# M4K2A register map
File version: 0.1
Registers are 32-bit, read-write, reset 0x0 unless marked. A register's access mark holds for its fields unless they carry their own. Offsets are from the block's base; [hi:lo] are bit positions; {n}, {i} and the like mark numbered series.

## PC — Port C
Base 0x400C0200
0x00 DATA — PC Data Register
  [0] PC0
0x04 CR — PC Control Register
  [0] PC0C
0x08 FR1 — PC Function Register 1
  [0] PC0F1
0x0C FR2 — PC Function Register 2
  [0] PC0F2
0x14 FR4 — PC Function Register 4
  [0] PC0F4
0x18 FR5 — PC Function Register 5
  [0] PC0F5
0x28 OD — PC Open Drain Control Register
  [0] PC0OD
0x2C PUP — PC Pull-up Control Register
  [0] PC0PUP
0x30 PDN — PC Pull-Down Control Register
  [0] PC0PDN
0x38 IE — PC Input Enable Control Register
  [0] PC0IE

## PD — Port D
Base 0x400C0300
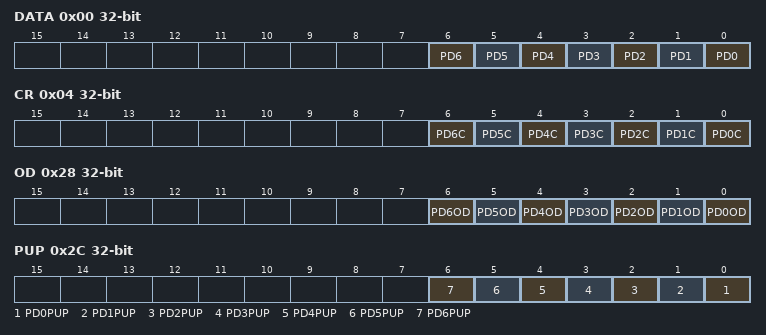
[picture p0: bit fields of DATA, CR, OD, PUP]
0x00 DATA — PD Data Register
  [n] PD{n} (n=0..6)
0x04 CR — PD Control Register
  [n] PD{n}C (n=0..6)
0x18 FR5 — PD Function Register 5
  [6] PD6F5
0x28 OD — PD Open Drain Control Register
  [n] PD{n}OD (n=0..6)
0x2C PUP — PD Pull-up Control Register
  [n] PD{n}PUP (n=0..6)
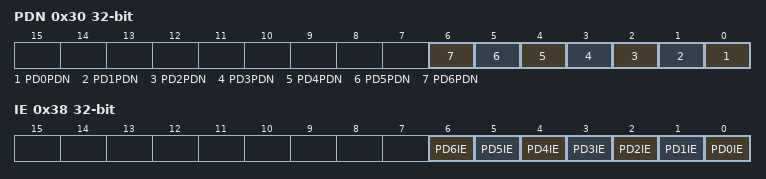
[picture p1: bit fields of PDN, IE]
0x30 PDN — PD Pull-Down Control Register
  [n] PD{n}PDN (n=0..6)
0x38 IE — PD Input Enable Control Register
  [n] PD{n}IE (n=0..6)

## PE — Port E
Base 0x400C0400
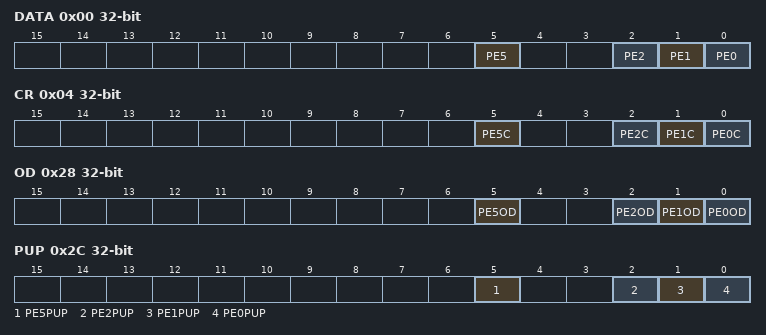
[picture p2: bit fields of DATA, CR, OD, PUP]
0x00 DATA — PE Data Register
  [5] PE5, [2] PE2, [1] PE1, [0] PE0
0x04 CR — PE Control Register
  [5] PE5C, [2] PE2C, [1] PE1C, [0] PE0C
0x28 OD — PE Open Drain Control Register
  [5] PE5OD, [2] PE2OD, [1] PE1OD, [0] PE0OD
0x2C PUP — PE Pull-up Control Register
  [5] PE5PUP, [2] PE2PUP, [1] PE1PUP, [0] PE0PUP
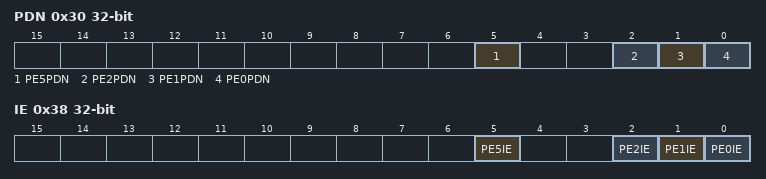
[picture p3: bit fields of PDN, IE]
0x30 PDN — PE Pull-Down Control Register
  [5] PE5PDN, [2] PE2PDN, [1] PE1PDN, [0] PE0PDN
0x38 IE — PE Input Enable Control Register
  [5] PE5IE, [2] PE2IE, [1] PE1IE, [0] PE0IE

## PF
Base 0x400C0500
0x00 DATA — PF Data Register
  [0] PF0
0x04 CR — PF Control Register
  [0] PF0C
{0x4+4i} FR{i} (i=4..7) — PF Function Register {i}
  [0] PF0F{i}
0x28 OD — PF Open Drain Control Register
  [0] PF0OD
0x2C PUP — PF Pull-up Control Register
  [0] PF0PUP
0x30 PDN — PF Pull-Down Control Register
  [0] PF0PDN
0x38 IE — PF Input Enable Control Register
  [0] PF0IE

## PG
Base 0x400C0600
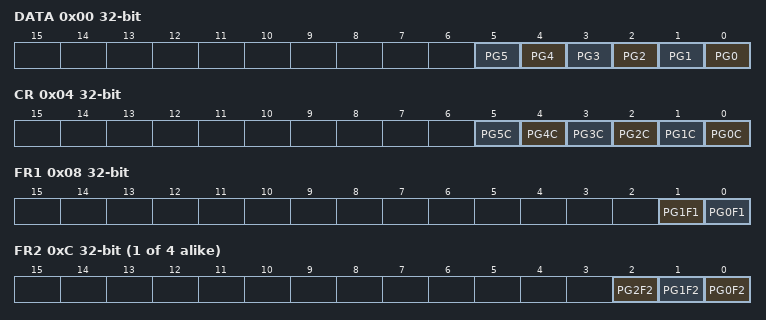
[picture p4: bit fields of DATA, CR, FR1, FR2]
0x00 DATA — PG Data Register
  [n] PG{n} (n=0..5)
0x04 CR — PG Control Register
  [n] PG{n}C (n=0..5)
0x08 FR1 — PG Function Register 1
  [1] PG1F1, [0] PG0F1
{0x4+4i} FR{i} (i=2..5) — PG Function Register {i}
  [2] PG2F{i}, [1] PG1F{i}, [0] PG0F{i}
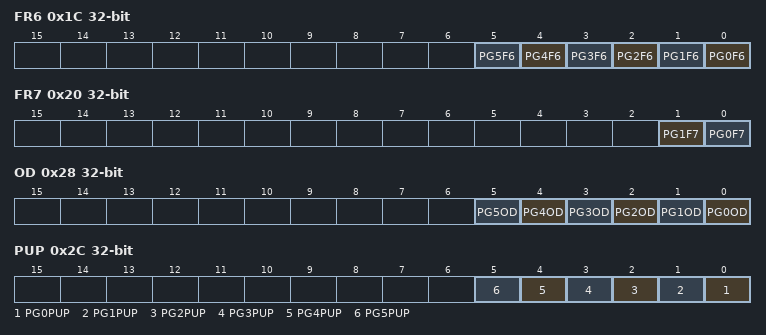
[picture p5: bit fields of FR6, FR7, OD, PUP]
0x1C FR6 — PG Function Register 6
  [n] PG{n}F6 (n=0..5)
0x20 FR7 — PG Function Register 7
  [1] PG1F7, [0] PG0F7
0x28 OD — PG Open Drain Control Register
  [n] PG{n}OD (n=0..5)
0x2C PUP — PG Pull-up Control Register
  [n] PG{n}PUP (n=0..5)
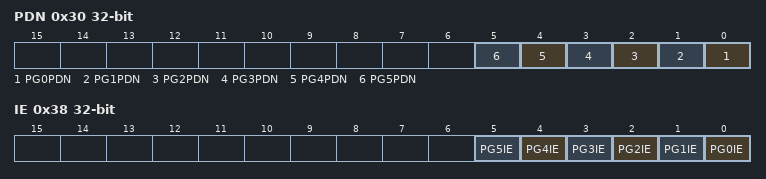
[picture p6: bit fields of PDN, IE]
0x30 PDN — PG Pull-Down Control Register
  [n] PG{n}PDN (n=0..5)
0x38 IE — PG Input Enable Control Register
  [n] PG{n}IE (n=0..5)

## PH
Base 0x400C0700
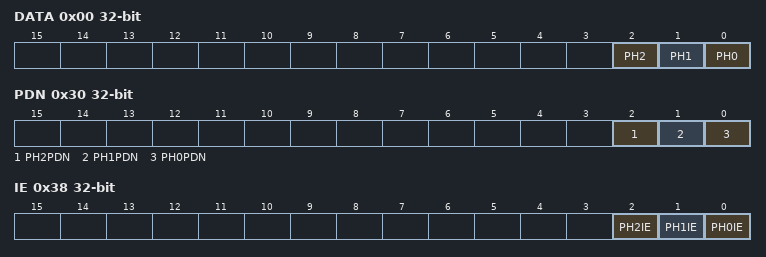
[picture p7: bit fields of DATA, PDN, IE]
0x00 DATA — PH Data Register
  [2] PH2, [1] PH1, [0] PH0
0x04 CR — PH Control Register
  [2] PH2C
0x18 FR5 — PH Function Register 5
  [2] PH2F5
0x28 OD — PH Open Drain Control Register
  [2] PH2OD
0x2C PUP — PH Pull-up Control Register
  [2] PH2PUP
0x30 PDN — PH Pull-Down Control Register
  [2] PH2PDN, [1] PH1PDN, [0] PH0PDN
0x38 IE — PH Input Enable Control Register
  [2] PH2IE, [1] PH1IE, [0] PH0IE

## PJ
Base 0x400C0800
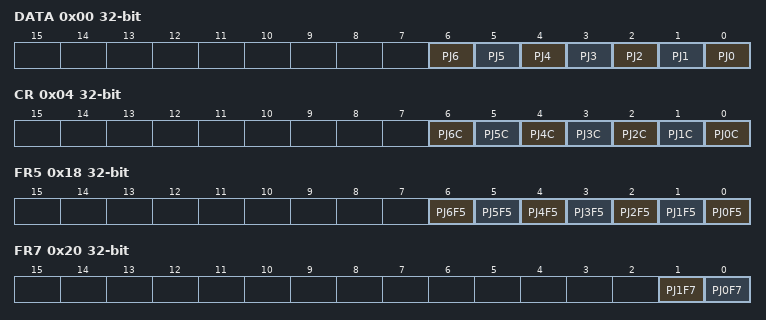
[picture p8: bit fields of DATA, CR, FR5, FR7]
0x00 DATA — PJ Data Register
  [n] PJ{n} (n=0..6)
0x04 CR — PJ Control Register
  [n] PJ{n}C (n=0..6)
0x18 FR5 — PJ Function Register 5
  [n] PJ{n}F5 (n=0..6)
0x1C FR6 — PJ Function Register 6
  [0] PJ0F6
0x20 FR7 — PJ Function Register 7
  [1] PJ1F7, [0] PJ0F7
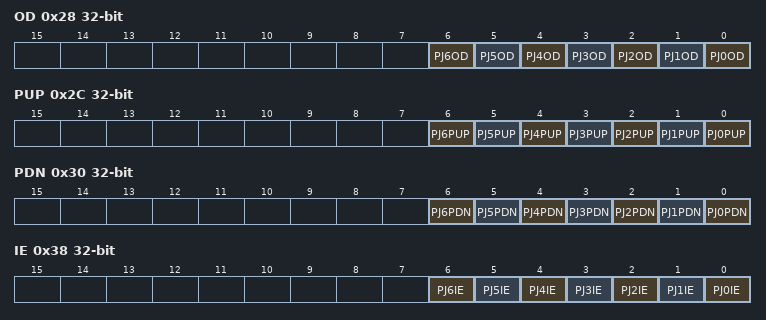
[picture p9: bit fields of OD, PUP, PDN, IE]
0x28 OD — PJ Open Drain Control Register
  [n] PJ{n}OD (n=0..6)
0x2C PUP — PJ Pull-up Control Register
  [n] PJ{n}PUP (n=0..6)
0x30 PDN — PJ Pull-Down Control Register
  [n] PJ{n}PDN (n=0..6)
0x38 IE — PJ Input Enable Control Register
  [n] PJ{n}IE (n=0..6)

## PK
Base 0x400C0900
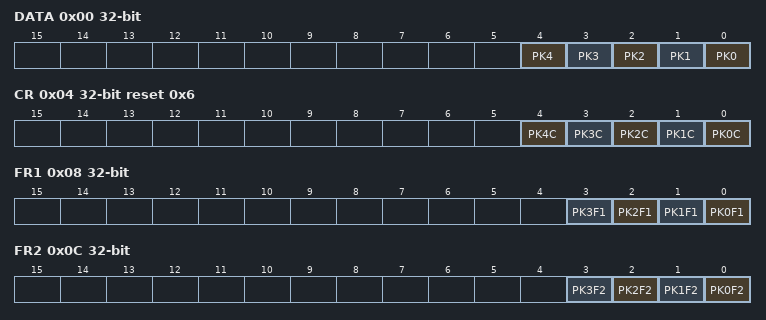
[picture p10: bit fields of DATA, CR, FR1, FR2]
0x00 DATA — PK Data Register
  [n] PK{n} (n=0..4)
0x04 CR reset 0x6 — PK Control Register
  [n] PK{n}C (n=0..4)
0x08 FR1 — PK Function Register 1
  [n] PK{n}F1 (n=0..3)
0x0C FR2 — PK Function Register 2
  [n] PK{n}F2 (n=0..3)
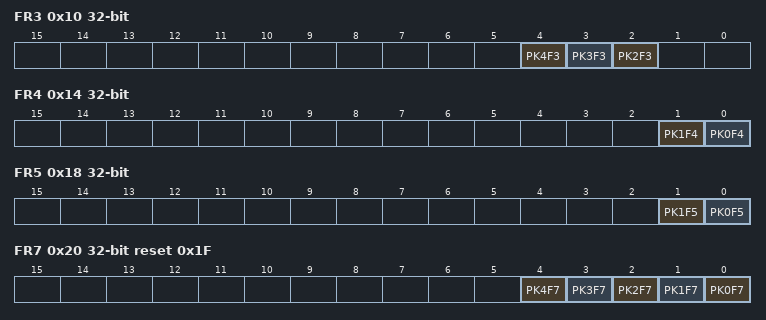
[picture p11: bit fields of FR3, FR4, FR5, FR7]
0x10 FR3 — PK Function Register 3
  [4] PK4F3, [3] PK3F3, [2] PK2F3
0x14 FR4 — PK Function Register 4
  [1] PK1F4, [0] PK0F4
0x18 FR5 — PK Function Register 5
  [1] PK1F5, [0] PK0F5
0x1C FR6 — PK Function Register 6
  [4] PK4F6
0x20 FR7 reset 0x1F — PK Function Register 7
  [n] PK{n}F7 (n=0..4)
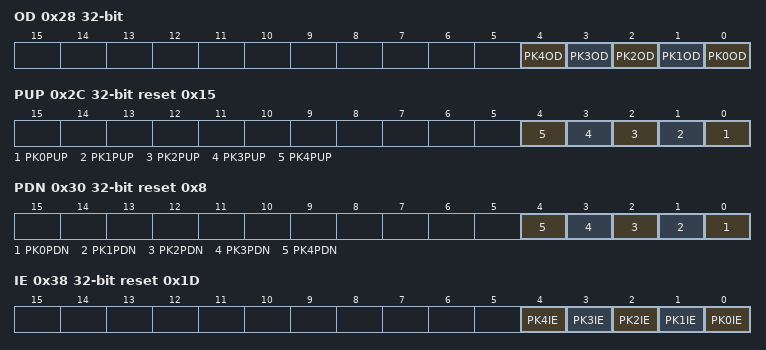
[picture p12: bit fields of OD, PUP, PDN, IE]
0x28 OD — PK Open Drain Control Register
  [n] PK{n}OD (n=0..4)
0x2C PUP reset 0x15 — PK Pull-up Control Register
  [n] PK{n}PUP (n=0..4)
0x30 PDN reset 0x8 — PK Pull-Down Control Register
  [n] PK{n}PDN (n=0..4)
0x38 IE reset 0x1D — PK Input Enable Control Register
  [n] PK{n}IE (n=0..4)
